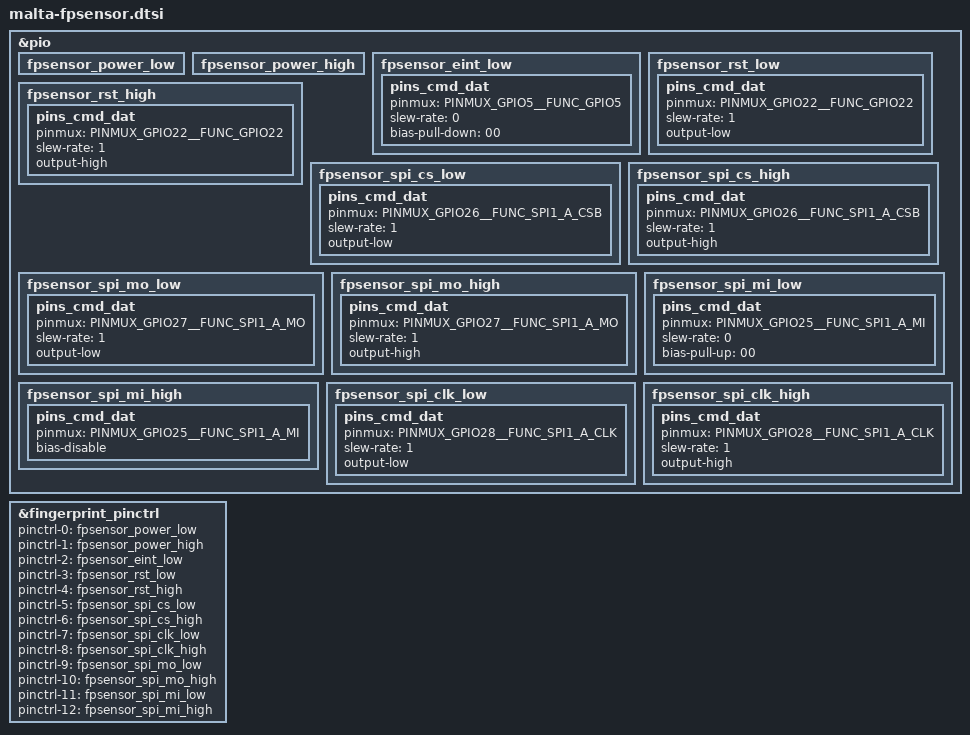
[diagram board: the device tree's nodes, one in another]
/* Copyright (c) 2014, The Linux Foundation. All rights reserved.
*
* This program is free software; you can redistribute it and/or modify
* it under the terms of the GNU General Public License version 2 and
* only version 2 as published by the Free Software Foundation.
*
* This program is distributed in the hope that it will be useful,
* but WITHOUT ANY WARRANTY; without even the implied warranty of
* MERCHANTABILITY or FITNESS FOR A PARTICULAR PURPOSE.  See the
* GNU General Public License for more details.
*/


/*begin, fps, fingerprint config*/
&pio{
    fpsensor_power_low: fpsensor_power_low {
    };
    fpsensor_power_high: fpsensor_power_high {
    };
    fpsensor_eint_low: fpsensor_eint_low {
        pins_cmd_dat {
            pinmux = <PINMUX_GPIO5__FUNC_GPIO5>;
            slew-rate = <0>;
            //bias-disable;
            bias-pull-down = <00>;
        };
    };
    fpsensor_rst_low: fpsensor_rst_low {
        pins_cmd_dat {
            pinmux = <PINMUX_GPIO22__FUNC_GPIO22>;
            slew-rate = <1>;
            output-low;
        };
    };
    fpsensor_rst_high: fpsensor_rst_high {
        pins_cmd_dat {
            pinmux = <PINMUX_GPIO22__FUNC_GPIO22>;
            slew-rate = <1>;
            output-high;
        };
    };
    fpsensor_spi_cs_low: fpsensor_spi_cs_low {
        pins_cmd_dat {
            pinmux = <PINMUX_GPIO26__FUNC_SPI1_A_CSB>;
            slew-rate = <1>;
            output-low;
        };
    };
    fpsensor_spi_cs_high: fpsensor_spi_cs_high {
        pins_cmd_dat {
            pinmux = <PINMUX_GPIO26__FUNC_SPI1_A_CSB>;
            slew-rate = <1>;
            output-high;
        };
    };
    fpsensor_spi_mo_low: fpsensor_spi_mo_low {
        pins_cmd_dat {
            pinmux = <PINMUX_GPIO27__FUNC_SPI1_A_MO>;
            slew-rate = <1>;
            output-low;
        };
    };
    fpsensor_spi_mo_high: fpsensor_spi_mo_high {
        pins_cmd_dat {
            pinmux = <PINMUX_GPIO27__FUNC_SPI1_A_MO>;
            slew-rate = <1>;
            output-high;
        };
    };
    fpsensor_spi_mi_low: fpsensor_spi_mi_low {
        pins_cmd_dat {
            pinmux = <PINMUX_GPIO25__FUNC_SPI1_A_MI>;
            slew-rate = <0>;
            bias-pull-up = <00>;
        };
    };
    fpsensor_spi_mi_high: fpsensor_spi_mi_high {
        pins_cmd_dat {
            pinmux = <PINMUX_GPIO25__FUNC_SPI1_A_MI>;
            bias-disable;
        };
    };
    fpsensor_spi_clk_low: fpsensor_spi_clk_low {
        pins_cmd_dat {
            pinmux = <PINMUX_GPIO28__FUNC_SPI1_A_CLK>;
            slew-rate = <1>;
            output-low;
        };
    };
    fpsensor_spi_clk_high: fpsensor_spi_clk_high {
        pins_cmd_dat {
            pinmux = <PINMUX_GPIO28__FUNC_SPI1_A_CLK>;
            slew-rate = <1>;
            output-high;
        };
    };
};
&fingerprint_pinctrl{
    pinctrl-names = "fpsensor_power_low", "fpsensor_power_high",
        "fpsensor_eint_low",
        "fpsensor_rst_low", "fpsensor_rst_high",
        "fpsensor_spi_cs_low", "fpsensor_spi_cs_high",
        "fpsensor_spi_clk_low", "fpsensor_spi_clk_high",
        "fpsensor_spi_mo_low", "fpsensor_spi_mo_high",
        "fpsensor_spi_mi_low", "fpsensor_spi_mi_high";
    pinctrl-0 = <&fpsensor_power_low>;
    pinctrl-1 = <&fpsensor_power_high>;
    pinctrl-2 = <&fpsensor_eint_low>;
    pinctrl-3 = <&fpsensor_rst_low>;
    pinctrl-4 = <&fpsensor_rst_high>;
    pinctrl-5 = <&fpsensor_spi_cs_low>;
    pinctrl-6 = <&fpsensor_spi_cs_high>;
    pinctrl-7 = <&fpsensor_spi_clk_low>;
    pinctrl-8 = <&fpsensor_spi_clk_high>;
    pinctrl-9 = <&fpsensor_spi_mo_low>;
    pinctrl-10 = <&fpsensor_spi_mo_high>;
    pinctrl-11 = <&fpsensor_spi_mi_low>;
    pinctrl-12 = <&fpsensor_spi_mi_high>;

    status = "okay";
};
/*end, fps, fingerprint config*/
